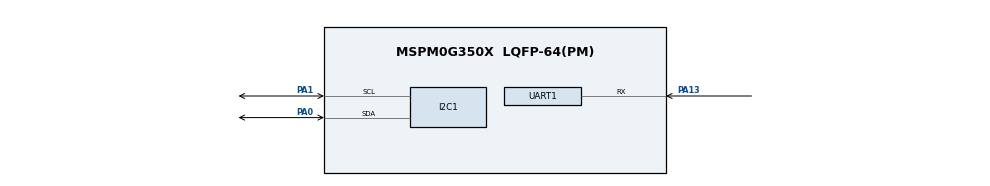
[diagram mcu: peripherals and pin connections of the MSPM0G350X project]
/**
 * @cliArgs --device "MSPM0G350X" --part "Default" --package "LQFP-64(PM)" --product "mspm0_sdk@2.09.00.01"
 * @versions {"tool":"1.25.0+4268"}
 */

/**
 * Import the modules used in this configuration.
 */
const I2C    = scripting.addModule("/ti/driverlib/I2C", {}, false);
const I2C1   = I2C.addInstance();
const SYSCTL = scripting.addModule("/ti/driverlib/SYSCTL");
const UART   = scripting.addModule("/ti/driverlib/UART", {}, false);
const UART1  = UART.addInstance();

/**
 * Write custom configuration values to the imported modules.
 */
const gate7  = system.clockTree["MFCLKGATE"];
gate7.enable = true;

I2C1.$name                     = "I2C_0";
I2C1.basicEnableController     = true;
I2C1.advControllerTXFIFOTRIG   = "BYTES_1";
I2C1.peripheral.$assign        = "I2C0";
I2C1.peripheral.sdaPin.$assign = "PA0";
I2C1.peripheral.sclPin.$assign = "PA1";
I2C1.sdaPinConfig.$name        = "ti_driverlib_gpio_GPIOPinGeneric0";
I2C1.sclPinConfig.$name        = "ti_driverlib_gpio_GPIOPinGeneric1";

const Board = scripting.addModule("/ti/driverlib/Board", {}, false);

SYSCTL.forceDefaultClkConfig = true;
SYSCTL.clockTreeEn           = true;

UART1.$name                    = "UART_0";
UART1.targetBaudRate           = 115200;
UART1.uartClkSrc               = "MFCLK";
UART1.enabledInterrupts        = ["RX"];
UART1.peripheral.rxPin.$assign = "PA13";
UART1.txPinConfig.$name        = "ti_driverlib_gpio_GPIOPinGeneric2";
UART1.rxPinConfig.$name        = "ti_driverlib_gpio_GPIOPinGeneric3";

/**
 * Pinmux solution for unlocked pins/peripherals. This ensures that minor changes to the automatic solver in a future
 * version of the tool will not impact the pinmux you originally saw.  These lines can be completely deleted in order to
 * re-solve from scratch.
 */
Board.peripheral.$suggestSolution          = "DEBUGSS";
Board.peripheral.swclkPin.$suggestSolution = "PA20";
Board.peripheral.swdioPin.$suggestSolution = "PA19";
UART1.peripheral.$suggestSolution          = "UART3";
UART1.peripheral.txPin.$suggestSolution    = "PA14";
